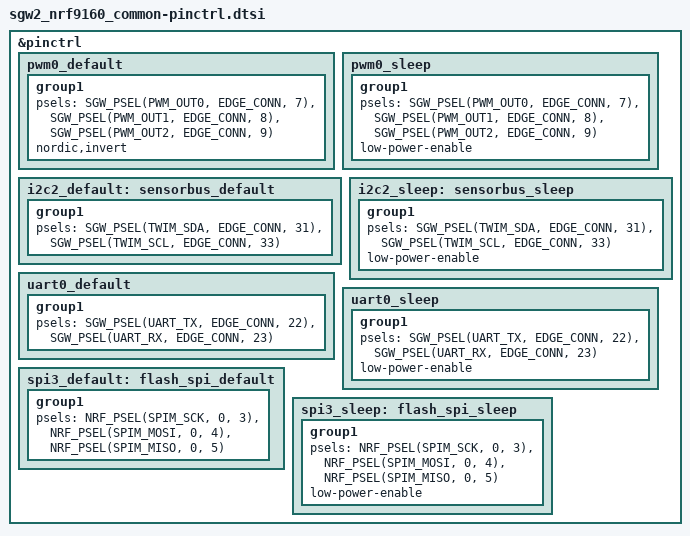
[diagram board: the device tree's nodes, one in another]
/*
 * Copyright (c) 2022 Nordic Semiconductor
 * Copyright (c) 2024 Sensoan Oy
 * SPDX-License-Identifier: Apache-2.0
 */

&pinctrl {
	pwm0_default: pwm0_default {
		group1 {
			psels = <SGW_PSEL(PWM_OUT0, EDGE_CONN, 7)>,
				<SGW_PSEL(PWM_OUT1, EDGE_CONN, 8)>,
				<SGW_PSEL(PWM_OUT2, EDGE_CONN, 9)>;
			nordic,invert;
		};
	};

	pwm0_sleep: pwm0_sleep {
		group1 {
			psels = <SGW_PSEL(PWM_OUT0, EDGE_CONN, 7)>,
				<SGW_PSEL(PWM_OUT1, EDGE_CONN, 8)>,
				<SGW_PSEL(PWM_OUT2, EDGE_CONN, 9)>;
			low-power-enable;
		};
	};

	i2c2_default: sensorbus_default: i2c2_default {
		group1 {
			psels = <SGW_PSEL(TWIM_SDA, EDGE_CONN, 31)>,
				<SGW_PSEL(TWIM_SCL, EDGE_CONN, 33)>;
		};
	};

	i2c2_sleep: sensorbus_sleep: i2c2_sleep {
		group1 {
			psels = <SGW_PSEL(TWIM_SDA, EDGE_CONN, 31)>,
				<SGW_PSEL(TWIM_SCL, EDGE_CONN, 33)>;
			low-power-enable;
		};
	};

	uart0_default: uart0_default {
		group1 {
			psels = <SGW_PSEL(UART_TX, EDGE_CONN, 22)>,
				<SGW_PSEL(UART_RX, EDGE_CONN, 23)>;
		};
	};

	uart0_sleep: uart0_sleep {
		group1 {
			psels = <SGW_PSEL(UART_TX, EDGE_CONN, 22)>,
				<SGW_PSEL(UART_RX, EDGE_CONN, 23)>;
			low-power-enable;
		};
	};

	spi3_default: flash_spi_default: spi3_default {
		group1 {
			psels = <NRF_PSEL(SPIM_SCK, 0, 3)>,
				<NRF_PSEL(SPIM_MOSI, 0, 4)>,
				<NRF_PSEL(SPIM_MISO, 0, 5)>;
		};
	};

	spi3_sleep: flash_spi_sleep: spi3_sleep {
		group1 {
			psels = <NRF_PSEL(SPIM_SCK, 0, 3)>,
				<NRF_PSEL(SPIM_MOSI, 0, 4)>,
				<NRF_PSEL(SPIM_MISO, 0, 5)>;
			low-power-enable;
		};
	};
};
